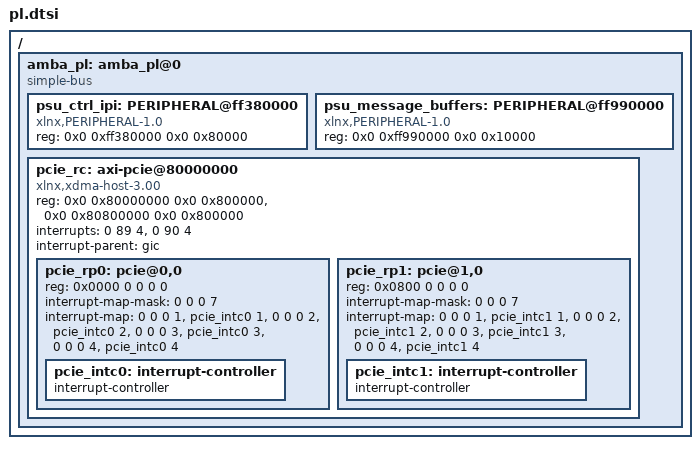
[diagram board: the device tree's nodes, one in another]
/*
 * CAUTION: This file is automatically generated by Xilinx.
 * Version: HSI 2019.1
 * Today is: Sat Jun  6 20:32:13 2020
 */


/ {
	amba_pl: amba_pl@0 {
		#address-cells = <2>;
		#size-cells = <2>;
		compatible = "simple-bus";
		ranges ;
		psu_ctrl_ipi: PERIPHERAL@ff380000 {
			/* This is a place holder node for a custom IP, user may need to update the entries */
			compatible = "xlnx,PERIPHERAL-1.0";
			reg = <0x0 0xff380000 0x0 0x80000>;
		};
		psu_message_buffers: PERIPHERAL@ff990000 {
			/* This is a place holder node for a custom IP, user may need to update the entries */
			compatible = "xlnx,PERIPHERAL-1.0";
			reg = <0x0 0xff990000 0x0 0x10000>;
		};

    pcie_rc: axi-pcie@80000000 {
      compatible = "xlnx,xdma-host-3.00";
		  device_type = "pci";
		  reg = <0x0 0x80000000 0x0 0x800000>, /*Root port 0*/
        <0x0 0x80800000 0x0 0x800000>; /*Root port 1*/
      reg-names = "rp0", "rp1";
		  #address-cells = <3>;
		  #size-cells = <2>;
		  ranges = <0x02000000 0x0 0xA0000000 0x0 0xA0000000 0x0 0x200000>;
		  #interrupt-cells = <1>;
		  interrupts = <0 89 4>,  /*Root port 0*/
                 <0 90 4>;  /*Root port 1*/
      interrupt-parent = <&gic>;

		  pcie_rp0: pcie@0,0 {
			  device_type = "pci";
			  reg = <0x0000 0 0 0 0>;
			  #address-cells = <3>;
			  #size-cells = <2>;
			  ranges;
			  #interrupt-cells = <1>;
			  interrupt-map-mask = <0 0 0 7>;
			  interrupt-map = <0 0 0 1 &pcie_intc0 1>,
				  <0 0 0 2 &pcie_intc0 2>,
				  <0 0 0 3 &pcie_intc0 3>,
				  <0 0 0 4 &pcie_intc0 4>;
			  pcie_intc0: interrupt-controller {
				  interrupt-controller;
				  #address-cells = <0>;
				  #interrupt-cells = <1>;
			  };
		  };

		  pcie_rp1: pcie@1,0 {
			  device_type = "pci";
			  reg = <0x0800 0 0 0 0>;
			  #address-cells = <3>;
			  #size-cells = <2>;
			  ranges;
			  #interrupt-cells = <1>;
			  interrupt-map-mask = <0 0 0 7>;
			  interrupt-map = <0 0 0 1 &pcie_intc1 1>,
				  <0 0 0 2 &pcie_intc1 2>,
				  <0 0 0 3 &pcie_intc1 3>,
				  <0 0 0 4 &pcie_intc1 4>;

			  pcie_intc1: interrupt-controller {
				  interrupt-controller;
				  #address-cells = <0>;
				  #interrupt-cells = <1>;
			  };
		  };
	  };
  };
};
